# TLE9263 register map
Vendor: Infineon; File version: 0.2
TLE9263 Family
Registers are 8-bit, read-write, no defined reset value unless marked. A register's access mark holds for its fields unless they carry their own. Offsets are from the block's base; lines under a group give offsets from that group; [hi:lo] are bit positions; {n}, {i} and the like mark numbered series; 'fields as' and 'values as' point back to an identical list; <NAME> marks a mode.

## Memory map
0x00000000 CTRL size 0x40 — Control
0x00000040 STAT size 0x40 — Status

## STAT — Status
Base 0x00000040
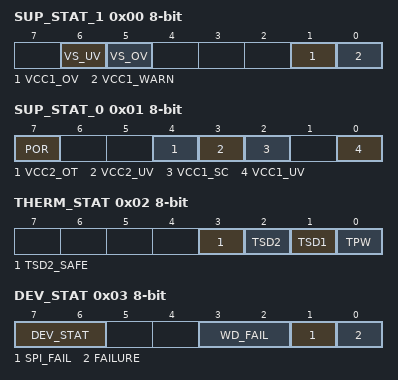
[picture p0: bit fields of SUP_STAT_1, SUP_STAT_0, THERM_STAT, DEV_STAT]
0x00 SUP_STAT_1 ro — Supply Voltage Fail Status
  [6] VS_UV — VS Undervoltage Detection (VS,UV)
    0=not_detected (No VS undervoltage detected); 1=detected (VS undervoltage detected (detection is only active when VCC1 is enabled - see also note below))
  [5] VS_OV — VS Overvoltage Detection (VS,UV)
    0=not_detected (No VS overvoltage detected); 1=detected (1) (VS overvoltage detected (detection is only active when VCC1 is enabled - see also note below))
  [1] VCC1_OV — VCC1 Overvoltage Detection ()
    0=not_detected (No VCC1 overvoltage warning); 1=detected (VCC1 overvoltage detected)
  [0] VCC1_WARN — VCC1 Undervoltage Prewarning ()
    0=not_detected (No VCC1 undervoltage prewarning); 1=detected (VCC1 undervoltage prewarning detected)
0x01 SUP_STAT_0 ro — Supply Voltage Fail Status
  [7] POR — Power-On Reset Detection
    0=not_detected (No POR); 1=detected (POR occurred)
  [4] VCC2_OT — VCC2 Over Temperature Detection
    0=not_detected (No over temperature); 1=detected (VCC2 over temperature detected)
  [3] VCC2_UV — VCC2 Under Voltage Detection ()
    0=not_detected (No VCC2 Under voltage); 1=detected (VCC2 under voltage detected)
  [2] VCC1_SC — VCC1 Short to GND Detection (<Vrtx for t>2ms after switch on)
    0=not_detected (No short); 1=detected (VCC1 short to GND detected)
  [0] VCC1_UV — VCC1 UV-Detection (due to Vrtx reset)
    0=not_detected (No VCC1_UV detection); 1=detected (VCC1 UV-Fail detected)
0x02 THERM_STAT ro — Thermal Protection Status
  [3] TSD2_SAFE — TSD2 Thermal Shut-Down Safe State Detection
    0=not_detected (No TSD2 safe state detected); 1=detected (TSD2 safe state detected: >16 consecutive TSD2 events occurred, next TSD2 waiting time will be 60s)
  [2] TSD2 — TSD2 Thermal Shut-Down Detection
    0=not_detected (No TSD2 event); 1=detected (TSD2 OT detected - leading to SBC Fail-Safe Mode)
  [1] TSD1 — TSD1 Thermal Shut-Down Detection
    0=not_detected (No TSD1 fail); 1=detected (TSD1 OT detected (affected module is disabled))
  [0] TPW — Thermal Pre Warning
    0=not_detected (No Thermal Pre warning); 1=detected (Thermal Pre warning detected)
0x03 DEV_STAT ro — Device Information Status
  [7:6] DEV_STAT — Device Status before Restart Mode
    0=Cleared (Register must be actively cleared); 1=failure (Restart due to failure (WD fail, TSD2, VCC1_UV, trial to access SLEEP MODE without any wake source activated); also after a wake from Fail-Safe Mode); 2=Sleep_Mode
  [3:2] WD_FAIL — Number of WD-Failure Events (1/2 WD failures depending on CFG1)
    0=not_detected (No WD Fail); 1=1x WD Fail, FO activation - Config 2 selected; 2=2x WD Fail, FO activation - Config 1 / 3 / 4 selected
  [1] SPI_FAIL — SPI Fail Information
    0=not_detected (No SPI fail); 1=detected (Invalid SPI command detected)
  [0] FAILURE — Activation of Fail Output FO
    0=not_detected (No Failure); 1=detected (Failure occurred)
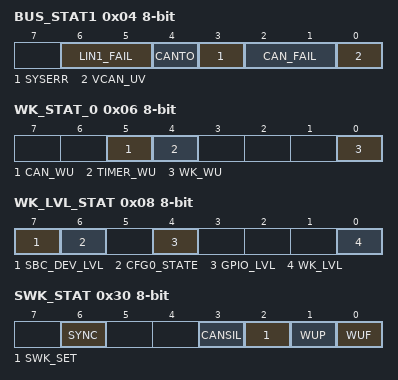
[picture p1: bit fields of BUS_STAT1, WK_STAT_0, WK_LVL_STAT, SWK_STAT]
0x04 BUS_STAT1 ro — Bus Communication Status
  [6:5] LIN1_FAIL — LIN1 Failure Status
    0=No error; 1=LIN1 TSD; 2=LIN1_TXD_DOM (TXD dominant time out for more than 20ms); 3=LIN1_BUS_DOM (BUS dominant time out for more than 20ms)
  [4] CANTO — CAN Time Out Detection
    0=not_detected (Normal operation); 1=detected (CAN Time Out detected)
  [3] SYSERR — SWK System Error
    0=not_detected (Selective Wake Mode is possible); 1=detected (System Error detected, SWK enabling not possible)
  [2:1] CAN_FAIL — CAN Failure Status
    0=none (No error); 1=TSD_shutdown (CAN TSD shutdown); 2=TXD_DOM (CAN_TXD_DOM: TXD dominant time out detected ()); 3=BUS_DOM (CAN_BUS_DOM: BUS dominant time out detected ())
  [0] VCAN_UV — Undervoltage CAN Bus Supply
    0=detected (Normal operation); 1=not_detected (CAN Supply undervoltage detected. Transmitter disabled)
0x05 BUS_STAT2 ro — Bus Communication Status
  [2:1] LIN2_FAIL — LIN2 Failure Status
    0=No_error; 1=LIN2_TSD_shutdown; 2=LIN2_TXD_DOM (TXD dominant time out for more than 20ms); 3=LIN2_BUS_DOM (BUS dominant time out for more than 20ms)
0x06 WK_STAT_0 ro — Wake-up Source and Information Status 0
  [all] fields
    0=not_detected (No Wake up); 1=detected (Wake up)
  [5] CAN_WU — Wake up via CAN Bus
  [4] TIMER_WU — Wake up via TimerX
  [0] WK_WU — Wake up via WK
0x07 WK_STAT_1 ro — Wake-up Source and Information Status 1
  [4] GPIO_WK_WU — Wake up via GPIO if configured as WK
    0=not_detected (No Wake up); 1=detected (Wake up)
0x08 WK_LVL_STAT ro — WK Input Level
  [7] SBC_DEV_LVL — Status of SBC Operating Mode at TEST Pin
    0=User Mode activated; 1=Development-Mode (SBC Development Mode activated)
  [6] CFG0_STATE — Device Configuration Status on pin INTN
    0=No_ext._Pull-up_Resisitor (No external pull-up resistor connected on INTN (Config 2/4)); 1=Ext._Pull-up_Resisitor (External pull-up resistor connected on INTN (Config 1/3))
  [4] GPIO_LVL — Status of GPIO if configured as GPIO (WK, LS or HS function)
    0=Low Level (=0); 1=High Level (=1)
  [0] WK_LVL — Status of WK
    0=Low Level (=0); 1=High Level (=1)
0x14 GPIO_OC_STAT ro — GPIO Overcurrent Status
  [6] GPIO_OC — Overcurrent Detection on GPIO (if configured as LS or HS)
    0=not_detected (No OC); 1=detected (OC detected)
0x15 GPIO_OL_STAT ro — GPIO Open-Load Status
  [6] GPIO_OL — Open-Load Detection on GPIO (if configured as HS)
    0=not_detected (No OL); 1=detected (OL detected)
0x30 SWK_STAT ro — Selective Wake Status
  [6] SYNC — Synchronisation (at least one CAN frame without fail must have been received)
    0=failed (SWK function not working or not synchronous to CAN bus); 1=Valid CAN frame received, SWK function is synchronous to CAN bus
  [3] CANSIL — CAN Silent Time during SWK operation
    0=not_exceeded (tsilence not exceeded); 1=exceeded (set if tsilence is exceeded.)
  [2] SWK_SET — Selective Wake Activity
    0=not_activated (Selective Wake is not active); 1=activated (Selective Wake is activated)
  [1] WUP — Wake-up Pattern Detection
    0=not_detected (No WUP); 1=detected (WUP detected)
  [0] WUF — SWK Wake-up Frame Detection (acc. ISO 11898-6)
    0=not_detected (No WUF); 1=detected (WUF detected)
0x31 SWK_ECNT_STAT ro — SWK Status
  [5:0] ECNT — SWK CAN Frame Error Counter
    0=No Frame Error; 31=31 Frame Errors have been counted; 32=overflow (Error counter overflow - SWK function will be disabled)
0x32 SWK_CDR_STAT1 ro — CDR Status 1 Register
  [7:0] NAVG_SAT — Output Value from Filter Block
0x33 SWK_CDR_STAT2 ro — CDR Status 2 Register
  [7:4] NAVG_SAT — Output Value from Filter Block
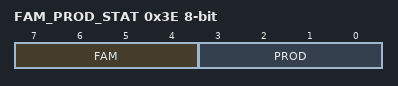
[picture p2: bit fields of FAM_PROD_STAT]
0x3E FAM_PROD_STAT ro — Family and Product Identification Register
  [7:4] FAM — SBC Family Identifier (bit4=LSB; bit7=MSB)
    1=HERA (Driver SBC Family (HERA)); 2=HERCULES (DC/DC-SBC Family (HERCULES)); 3=ATHENA (Mid-Range SBC Family (ATHENA)); 4=MCP (Multi-CAN SBC Family (MCP)); 5=LITE (LITE SBC Family (LITE)); 7=ATHENA+ (Mid-Range+ SBC Family (ATHENA+))
  [3:0] PROD — SBC Product Identifier (bit0=LSB; bit3=MSB)
    4=TLE9461ES (TLE9461ES (VCC1 = 5V, no SWK)); 5=TLE9461ESV33 (TLE9461ESV33 (VCC1 = 3.3V, no SWK)); 6=TLE9461-3ES (TLE9461-3ES (VCC1 = 5V, SWK) (default value if device is not fused)); 7=TLE9461-3ESV33 (TLE9461-3ESV33 (VCC1 = 3.3V, SWK)); 12=TLE9471ES (TLE9471ES (VCC1 = 5V, no SWK)); 13=TLE9471ESV33 (TLE9471ESV33 (VCC1 = 3.3V, no SWK)); 14=TLE9471-3ES (TLE9471-3ES(VCC1 = 5V, SWK)); 15=TLE9471-3ESV33 (TLE9471-3ESV33 (VCC1 = 3.3V, SWK))
